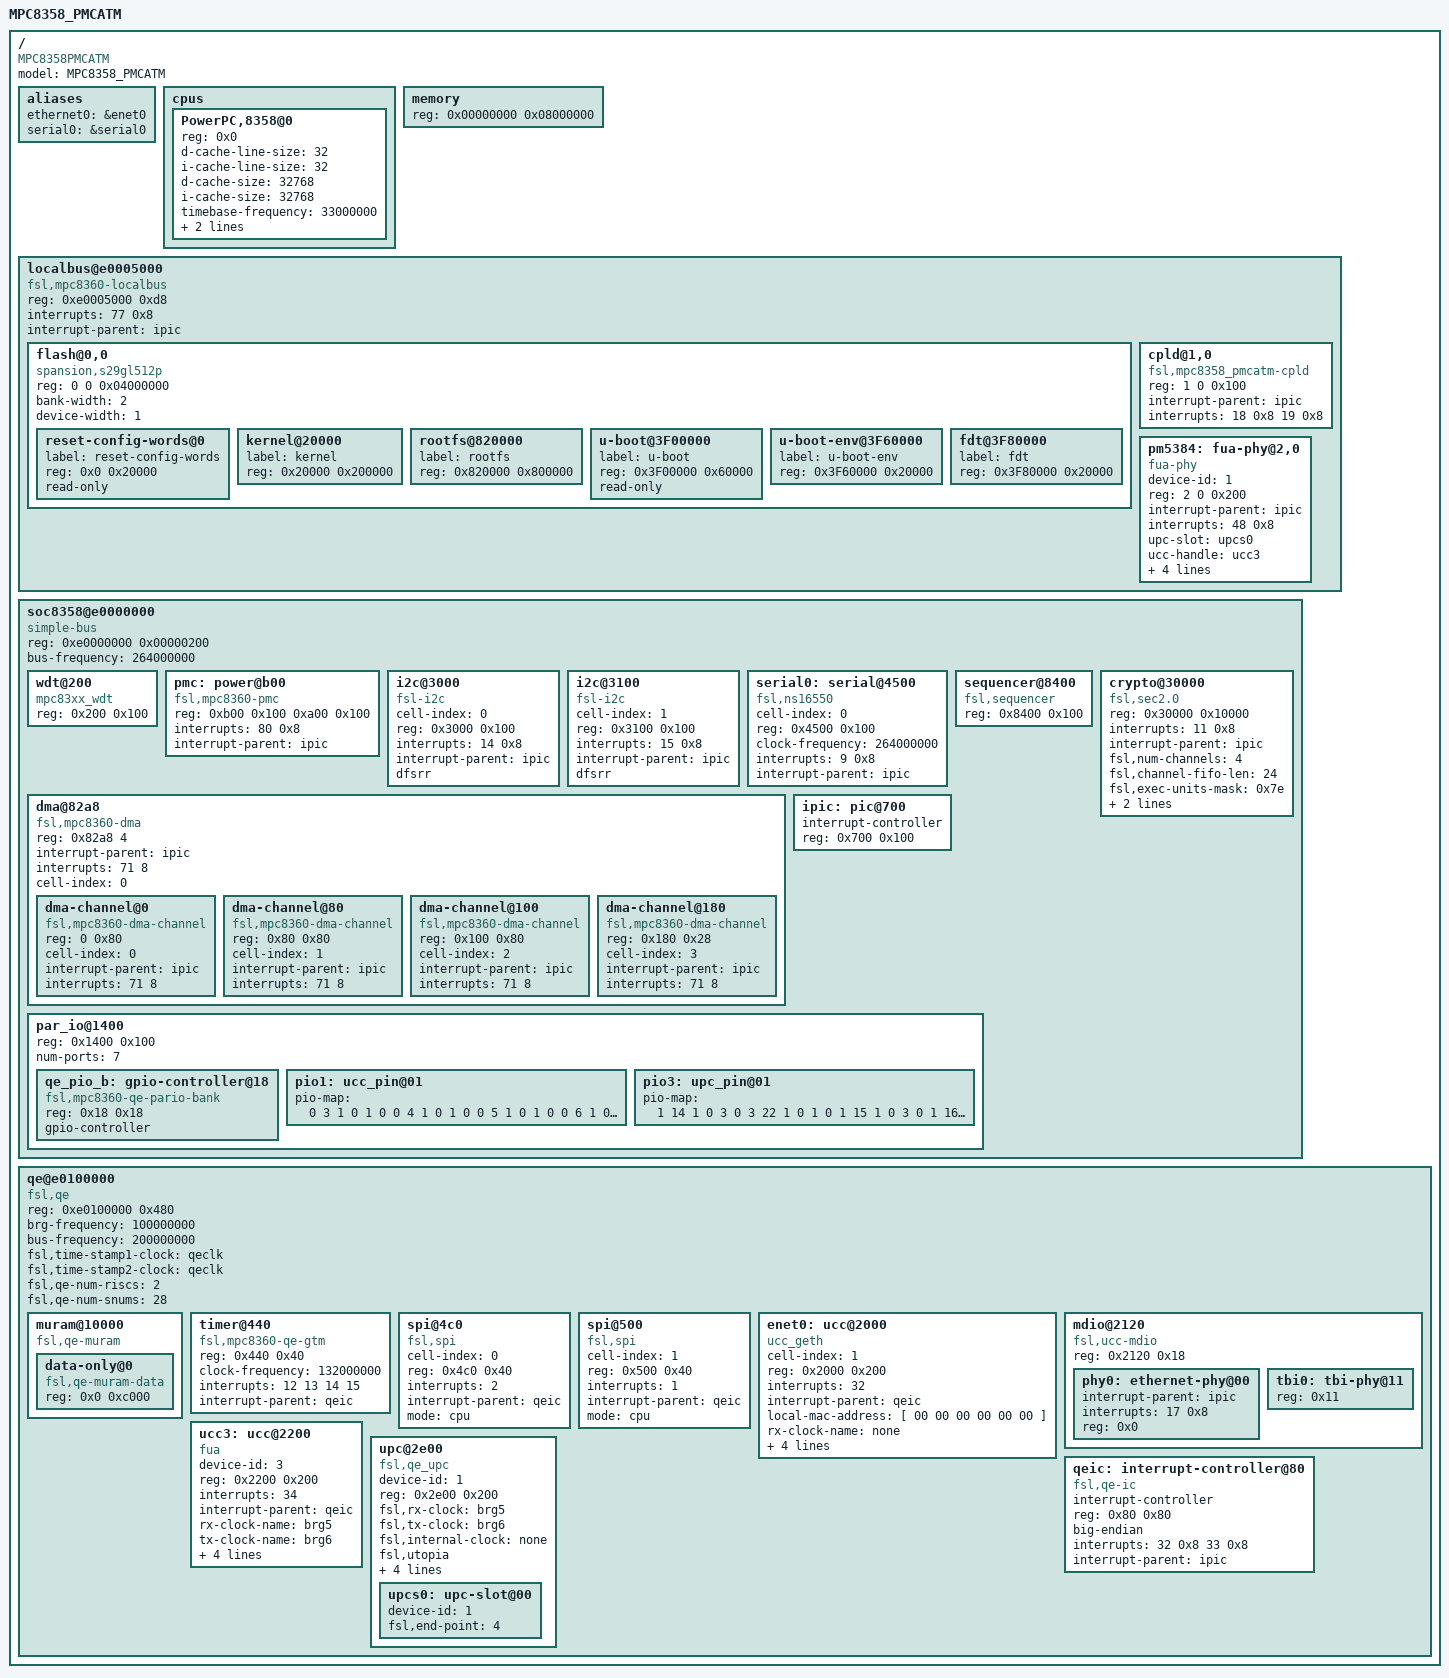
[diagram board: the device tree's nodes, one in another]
/*
 * BEC PMC-ATM MPC8358 Device Tree Source
 *
 * Copyright 2012 Beyond Electronics Corp
 *
 * Based on mpc836x_mds.dts
 *   Copyright 2006 Freescale Semiconductor Inc.
 *
 * This program is free software; you can redistribute  it and/or modify it
 * under  the terms of  the GNU General  Public License as published by the
 * Free Software Foundation;  either version 2 of the  License, or (at your
 * option) any later version.
 */


/dts-v1/;

/ {
	model = "MPC8358_PMCATM";
	compatible = "MPC8358PMCATM", "MPC8358_PMC-ATM", "MPC836xPMCATM";
	#address-cells = <1>;
	#size-cells = <1>;

	aliases {
		ethernet0 = &enet0;
		serial0 = &serial0;
	};

	cpus {
		#address-cells = <1>;
		#size-cells = <0>;

		PowerPC,8358@0 {
			device_type = "cpu";
			reg = <0x0>;
			d-cache-line-size = <32>;	// 32 bytes
			i-cache-line-size = <32>;	// 32 bytes
			d-cache-size = <32768>;		// L1, 32K
			i-cache-size = <32768>;		// L1, 32K
			timebase-frequency = <33000000>;
			bus-frequency = <264000000>;
			clock-frequency = <400000000>;
		};
	};

	/* 128MB DDR2 RAM */
	memory {
		device_type = "memory";
		reg = <0x00000000 0x08000000>;
	};

	localbus@e0005000 {
		#address-cells = <2>;
		#size-cells = <1>;
		#interrupt-cells = <2>;
		compatible = "fsl,mpc8360-localbus", "fsl,pq2pro-localbus",
			     "simple-bus";
		reg = <0xe0005000 0xd8>;
		ranges = <0 0 0xfc000000 0x04000000		/* 64MB Flash */
		          1 0 0xf8000000 0x00000100		/* CPLD */
		          2 0 0xf9000000 0x00000400>;		/* ATM Suni PHY - PMC-Sierra PM5384 */
		interrupts = <77 0x8>;
		interrupt-parent = <&ipic>;

		/* Flash starts at 0xFC000000, mtd partitions are specified as offsets */
		flash@0,0 {
			compatible = "spansion,s29gl512p", "cfi-flash";
			reg = <0 0 0x04000000>;
			bank-width = <2>;
			device-width = <1>;
			#address-cells = <1>;
			#size-cells = <1>;

			/* 1st sector contains RCWL and RCWH that configures the CPU clocks etc */
			reset-config-words@0 {
				label = "reset-config-words";
				reg = <0x0 0x20000>;
				read-only;
			};
			/* linux kernel 2MB - 16 sectors */
			kernel@20000 {
				label = "kernel";
				reg = <0x20000 0x200000>;
			};
			/* Root Filesystem (squashfs) - 8MB = 64 sectors */
			rootfs@820000 {
				label = "rootfs";
				reg = <0x820000 0x800000>;
			};
			/* CPU starts running u-boot code from 0xFFF00100 - 3 sectors */
			u-boot@3F00000 {
				label = "u-boot";
				reg = <0x3F00000 0x60000>;
				read-only;
			};
			/* u-boot environment - 1 sector */
			u-boot-env@3F60000 {
				label = "u-boot-env";
				reg = <0x3F60000 0x20000>;
			};
			/* Flattened Device Tree (fdt) - 1 sector */
			fdt@3F80000 {
				label = "fdt";
				reg = <0x3F80000 0x20000>;
			};
		};

		cpld@1,0 {
//			#address-cells = <1>;
//			#size-cells = <1>;
 			compatible = "fsl,mpc8358_pmcatm-cpld";
			reg = <1 0 0x100>;
			interrupt-parent = < &ipic >;
			interrupts = <18 0x8 19 0x8>;
		};

		pm5384: fua-phy@2,0 {
			device_type = "atm phy";
			compatible = "fua-phy";
			device-id = <1>;
			reg = <2 0 0x200>;
			interrupt-parent = < &ipic >;
			interrupts = <48 0x8>;
			upc-slot = < &upcs0 >;
			ucc-handle = < &ucc3 >;

			line_bitr = <155000000>;
			max_bitr = <155000000>;
			min_bitr = <50000000>;
			port-width = <1>;	// 0 = 8 bit Utopia, 1 = 16 bit Utopia
		};

	};

	soc8358@e0000000 {
		#address-cells = <1>;
		#size-cells = <1>;
		device_type = "soc";
		compatible = "simple-bus";
		ranges = <0x0 0xe0000000 0x00100000>;
		reg = <0xe0000000 0x00000200>;
		bus-frequency = <264000000>;

		wdt@200 {
			device_type = "watchdog";
			compatible = "mpc83xx_wdt";
			reg = <0x200 0x100>;
		};

		pmc: power@b00 {
			compatible = "fsl,mpc8360-pmc", "fsl,mpc8349-pmc";
			reg = <0xb00 0x100 0xa00 0x100>;
			interrupts = <80 0x8>;
			interrupt-parent = <&ipic>;
		};

		i2c@3000 {
			#address-cells = <1>;
			#size-cells = <0>;
			cell-index = <0>;
			compatible = "fsl-i2c";
			reg = <0x3000 0x100>;
			interrupts = <14 0x8>;
			interrupt-parent = <&ipic>;
			dfsrr;
		};

		i2c@3100 {
			#address-cells = <1>;
			#size-cells = <0>;
			cell-index = <1>;
			compatible = "fsl-i2c";
			reg = <0x3100 0x100>;
			interrupts = <15 0x8>;
			interrupt-parent = <&ipic>;
			dfsrr;
		};

		serial0: serial@4500 {
			cell-index = <0>;
			device_type = "serial";
			compatible = "fsl,ns16550", "ns16550";
			reg = <0x4500 0x100>;
			clock-frequency = <264000000>;
			interrupts = <9 0x8>;
			interrupt-parent = <&ipic>;
		};

		dma@82a8 {
			#address-cells = <1>;
			#size-cells = <1>;
			compatible = "fsl,mpc8360-dma", "fsl,elo-dma";
			reg = <0x82a8 4>;
			ranges = <0 0x8100 0x1a8>;
			interrupt-parent = <&ipic>;
			interrupts = <71 8>;
			cell-index = <0>;
			dma-channel@0 {
				compatible = "fsl,mpc8360-dma-channel", "fsl,elo-dma-channel";
				reg = <0 0x80>;
				cell-index = <0>;
				interrupt-parent = <&ipic>;
				interrupts = <71 8>;
			};
			dma-channel@80 {
				compatible = "fsl,mpc8360-dma-channel", "fsl,elo-dma-channel";
				reg = <0x80 0x80>;
				cell-index = <1>;
				interrupt-parent = <&ipic>;
				interrupts = <71 8>;
			};
			dma-channel@100 {
				compatible = "fsl,mpc8360-dma-channel", "fsl,elo-dma-channel";
				reg = <0x100 0x80>;
				cell-index = <2>;
				interrupt-parent = <&ipic>;
				interrupts = <71 8>;
			};
			dma-channel@180 {
				compatible = "fsl,mpc8360-dma-channel", "fsl,elo-dma-channel";
				reg = <0x180 0x28>;
				cell-index = <3>;
				interrupt-parent = <&ipic>;
				interrupts = <71 8>;
			};
		};

		sequencer@8400 {
			compatible = "fsl,sequencer";
			reg = <0x8400 0x100>;
		};

		crypto@30000 {
			compatible = "fsl,sec2.0";
			reg = <0x30000 0x10000>;
			interrupts = <11 0x8>;
			interrupt-parent = <&ipic>;
			fsl,num-channels = <4>;
			fsl,channel-fifo-len = <24>;
			fsl,exec-units-mask = <0x7e>;
			fsl,descriptor-types-mask = <0x01010ebf>;
			sleep = <&pmc 0x03000000>;
		};

		ipic: pic@700 {
			interrupt-controller;
			#address-cells = <0>;
			#interrupt-cells = <2>;
			reg = <0x700 0x100>;
			device_type = "ipic";
		};

		par_io@1400 {
			#address-cells = <1>;
			#size-cells = <1>;
			reg = <0x1400 0x100>;
			ranges = <0 0x1400 0x100>;
			device_type = "par_io";
			num-ports = <7>;

			qe_pio_b: gpio-controller@18 {
				#gpio-cells = <2>;
				compatible = "fsl,mpc8360-qe-pario-bank",
					     "fsl,mpc8323-qe-pario-bank";
				reg = <0x18 0x18>;
				gpio-controller;
			};

			pio1: ucc_pin@01 {
				pio-map = <
			/* see documentation: Documentation/devicetree/bindings/powerpc/fsl/cpm_qe/qe/pincfg.txt  */
			/* port  pin  dir  open_drain  assignment  has_irq */
					0  3  1  0  1  0 	/* TxD0 */
					0  4  1  0  1  0 	/* TxD1 */
					0  5  1  0  1  0 	/* TxD2 */
					0  6  1  0  1  0 	/* TxD3 */
					0  9  2  0  1  0 	/* RxD0 */
					0  10 2  0  1  0 	/* RxD1 */
					0  11 2  0  1  0 	/* RxD2 */
					0  12 2  0  1  0 	/* RxD3 */
					0  7  1  0  1  0 	/* TX_EN */
					0  15 2  0  1  0 	/* RX_DV */
					0  0  2  0  1  0 	/* RX_CLK */
					2  9  1  0  3  0 	/* GTX_CLK - CLK10 */
					2  8  2  0  1  0	/* GTX125 - CLK9 */
					0  1  3  0  2  0    /* MDIO */
					0  2  1  0  1  0    /* MDC */
					1 10  1  0  0  0    /* KILL_125_IN */
					1 11  1  0  0  0    /* COMA_IN */
					1 12  1  0  0  0    /* ETH_RESET_IN */
					>;
			};

			pio3: upc_pin@01 {
				pio-map = <
				/* port  pin  dir  open_drain  assignment  has_irq */
				/* UPC1 in Tx master mode */
					1  14 1  0  3  0   /* TxSOC */
					3  22 1  0  1  0   /* TxPRTY */
					1  15 1  0  3  0   /* TxENB[0] */
					1  16 2  0  1  0   /* TxCLAV[0] */
					4  3  1  0  2  0   /* TxADDR[0] */
					4  8  1  0  3  0   /* TxADDR[1] */
					4  12 1  0  2  0   /* TxADDR[2] */
					4  1  1  0  2  0   /* TxADDR[3] */
					4  13 1  0  3  0   /* TxADDR[4] */
                    3  4  1  0  3  0   /* TxDATA[0] */
					3  3  1  0  2  0   /* TxDATA[1] */
					3  2  1  0  2  0   /* TxDATA[2] */
					3  1  1  0  3  0   /* TxDATA[3] */
					3  0  1  0  3  0   /* TxDATA[4] */
					1  27 1  0  2  0   /* TxDATA[5] */
					1  26 1  0  1  0   /* TxDATA[6] */
					1  25 1  0  1  0   /* TxDATA[7] */
					1  24 1  0  1  0   /* TxDATA[8] */
					1  23 1  0  1  0   /* TxDATA[9] */
					1  22 1  0  1  0   /* TxDATA[10] */
					1  21 1  0  2  0   /* TxDATA[11] */
					1  20 1  0  2  0   /* TxDATA[12] */
					1  19 1  0  3  0   /* TxDATA[13] */
					1  18 1  0  2  0   /* TxDATA[14] */
					1  17 1  0  2  0   /* TxDATA[15] */
				/* UPC1 in Rx master mode */
					3  5  2  0  1  0  /* RxSCO */
					3  19 2  0  3  0  /* RxPRTY */
					3  6  1  0  3  0  /* RxENB */
					3  7  2  0  3  0  /* RxCLAV */
					4  2  1  0  2  0  /* RxADDR[0] */
					4  5  1  0  3  0  /* RxADDR[1] */
					4  4  1  0  2  0  /* RxADDR[2] */
					4  11 1  0  1  0  /* RxADDR[3] */
					4  7  1  0  2  0  /* RxADDR[4] */
					3  27 2  0  3  0  /* RxDATA[0] */
					3  26 2  0  2  0  /* RxDATA[1] */
					3  25 2  0  2  0  /* RxDATA[2] */
					3  24 2  0  2  0  /* RxDATA[3] */
					3  23 2  0  3  0  /* RxDATA[4] */
					3  21 2  0  3  0  /* RxDATA[5] */
					3  20 2  0  3  0  /* RxDATA[6] */
					3  18 2  0  2  0  /* RxDATA[7] */
					3  15 2  0  3  0  /* RxDATA[8] */
					3  14 2  0  3  0  /* RxDATA[9] */
					3  13 2  0  3  0  /* RxDATA[10] */
					3  12 2  0  2  0  /* RxDATA[11] */
					3  11 2  0  3  0  /* RxDATA[12] */
					3  10 2  0  3  0  /* RxDATA[13] */
					3  9  2  0  2  0  /* RxDATA[14] */
					3  8  2  0  3  0  /* RxDATA[15] */
				/* Tx clock and Rx clock */
					2  7  1  0  3  0  /* Tx clock BRGO6 (from CLK15) */
					2  5  1  0  2  0>;/* Rx clock BRGO5 (from CLK13) */
				};

		};
	};

	qe@e0100000 {
		#address-cells = <1>;
		#size-cells = <1>;
		device_type = "qe";
		compatible = "fsl,qe";
		ranges = <0x0 0xe0100000 0x00100000>;
		reg = <0xe0100000 0x480>;
		brg-frequency = <100000000>;
		bus-frequency = <200000000>;
		fsl,time-stamp1-clock = "qeclk";
		fsl,time-stamp2-clock = "qeclk";
		fsl,qe-num-riscs = <2>;
		fsl,qe-num-snums = <28>;

		muram@10000 {
 			#address-cells = <1>;
 			#size-cells = <1>;
			compatible = "fsl,qe-muram", "fsl,cpm-muram";
			ranges = <0x0 0x00010000 0x0000c000>;

			data-only@0 {
				compatible = "fsl,qe-muram-data",
					     "fsl,cpm-muram-data";
				reg = <0x0 0xc000>;
			};
		};

		timer@440 {
			compatible = "fsl,mpc8360-qe-gtm",
				     "fsl,qe-gtm", "fsl,gtm";
			reg = <0x440 0x40>;
			clock-frequency = <132000000>;
			interrupts = <12 13 14 15>;
			interrupt-parent = <&qeic>;
		};

		spi@4c0 {
			cell-index = <0>;
			compatible = "fsl,spi";
			reg = <0x4c0 0x40>;
			interrupts = <2>;
			interrupt-parent = <&qeic>;
			mode = "cpu";
		};

		spi@500 {
			cell-index = <1>;
			compatible = "fsl,spi";
			reg = <0x500 0x40>;
			interrupts = <1>;
			interrupt-parent = <&qeic>;
			mode = "cpu";
		};

		enet0: ucc@2000 {
			device_type = "network";
			compatible = "ucc_geth";
			cell-index = <1>;
			reg = <0x2000 0x200>;
			interrupts = <32>;
			interrupt-parent = <&qeic>;
			local-mac-address = [ 00 00 00 00 00 00 ];
			rx-clock-name = "none";
			tx-clock-name = "clk9";
			phy-handle = <&phy0>;
			phy-connection-type = "rgmii-id";
			pio-handle = <&pio1>;
		};

		mdio@2120 {
			#address-cells = <1>;
			#size-cells = <0>;
			reg = <0x2120 0x18>;
			compatible = "fsl,ucc-mdio";

			phy0: ethernet-phy@00 {
				interrupt-parent = <&ipic>;
				interrupts = <17 0x8>;
				reg = <0x0>;
				device_type = "ethernet-phy";
			};

			tbi0: tbi-phy@11 {
				reg = <0x11>;
				device_type = "tbi-phy";
			};
		};

		ucc3: ucc@2200 {
			device_type = "atm";
			compatible = "fua";
//			model = "UCC";
			device-id = <3>;
			reg = <0x2200 0x200>;
			interrupts = <34>;
			interrupt-parent = < &qeic >;
			rx-clock-name = "brg5";
			tx-clock-name = "brg6";
			pio-handle = < &pio3 >;
			multithread;
			threads = <16>;
			local-mac-address = [ 00 00 0B 50 61 DB ];
		};

		upc@2e00 {
			#address-cells = <1>;
			#size-cells = <0>;
			device_type = "upc";
			compatible = "fsl,qe_upc";
			device-id = <1>;
			reg = <0x2e00 0x200>;
			fsl,rx-clock = "brg5";
			fsl,tx-clock = "brg6";
			fsl,internal-clock = "none";
			fsl,utopia;
			fsl,tx-slave = <0>;
			fsl,rx-slave = <0>;
			fsl,address-mode = <0>;
			pio-handle = < &pio3 >;

			upcs0: upc-slot@00 {
				device_type = "upc-slot";
				device-id = <1>;
				fsl,end-point = <4>;
			};
		};


		qeic: interrupt-controller@80 {
			interrupt-controller;
			compatible = "fsl,qe-ic";
			#address-cells = <0>;
			#interrupt-cells = <1>;
			reg = <0x80 0x80>;
			big-endian;
			interrupts = <32 0x8 33 0x8>; // high:32 low:33
			interrupt-parent = <&ipic>;
		};
	};
};
